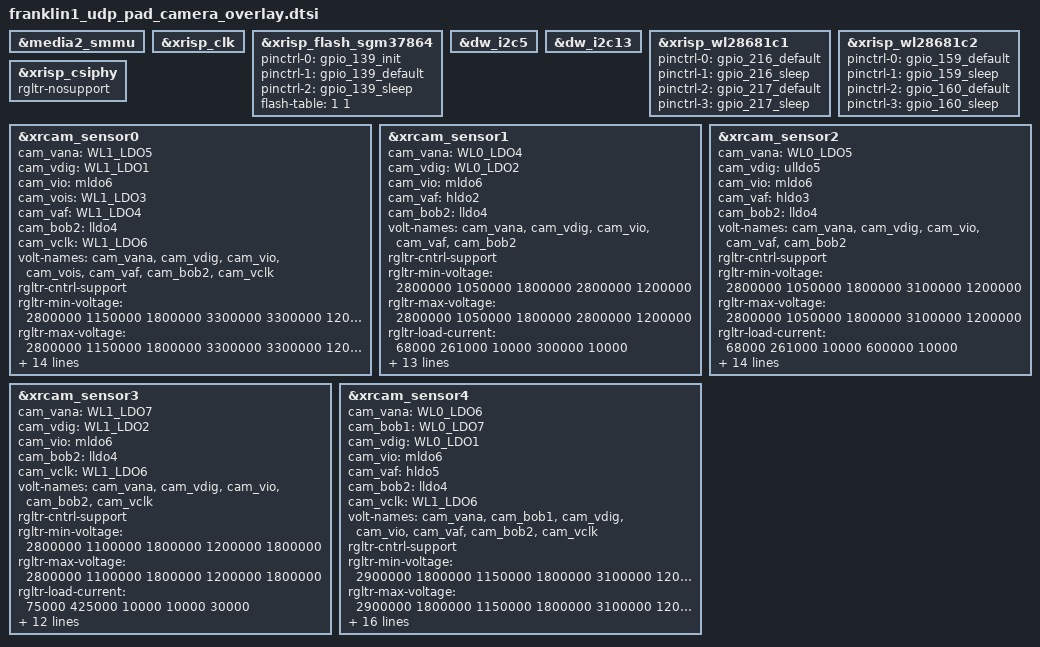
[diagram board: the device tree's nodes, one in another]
// SPDX-License-Identifier: GPL-2.0+
/*
 * vpu subsystem overlay dts for X-Ring Franklin
 *
 * (C) Copyright 2023 - 2023, X-Ring, Inc.
 */

#include <dt-bindings/xring/xr-o1-clock.h>

&media2_smmu {
	status = "okay";
};

&xrisp_clk {
	status = "okay";
};

&xrisp_flash_sgm37864 {
	status = "okay";
	pinctrl-names = "init", "default", "sleep";
	pinctrl-0 = <&gpio_139_init>;
	pinctrl-1 = <&gpio_139_default>;
	pinctrl-2 = <&gpio_139_sleep>;
	flash-table = <1 1>;
};

&dw_i2c5 {
	status = "okay";
};

&dw_i2c13 {
	status = "okay";
};

&xrisp_wl28681c1 {
	status = "okay";
	pinctrl-names ="gpio_216_default","gpio_216_sleep",
			"gpio_217_default","gpio_217_sleep";
	pinctrl-0 = <&gpio_216_default>;
	pinctrl-1 = <&gpio_216_sleep>;
	pinctrl-2 = <&gpio_217_default>;
	pinctrl-3 = <&gpio_217_sleep>;
};

&xrisp_wl28681c2 {
	status = "okay";
	pinctrl-names ="gpio_159_default","gpio_159_sleep",
			"gpio_160_default","gpio_160_sleep";
	pinctrl-0 = <&gpio_159_default>;
	pinctrl-1 = <&gpio_159_sleep>;
	pinctrl-2 = <&gpio_160_default>;
	pinctrl-3 = <&gpio_160_sleep>;
};

&xrisp_csiphy {
	status = "okay";
	rgltr-nosupport;
};

&xrcam_sensor0 {
	status = "okay";
	cam_vana  = "WL1_LDO5";
	cam_vdig  = "WL1_LDO1";
	cam_vio   = "mldo6";
	cam_vois  = "WL1_LDO3";
	cam_vaf   = "WL1_LDO4";
	cam_bob2  = "lldo4";
	cam_vclk  = "WL1_LDO6";
	volt-names = "cam_vana", "cam_vdig", "cam_vio",
		"cam_vois", "cam_vaf", "cam_bob2", "cam_vclk";
	rgltr-cntrl-support;
	rgltr-min-voltage = <2800000 1150000 1800000 3300000 3300000 1200000 1800000>;
	rgltr-max-voltage = <2800000 1150000 1800000 3300000 3300000 1200000 1800000>;
	rgltr-load-current = <195000 990000 10000 300000 3000000 10000 30000>;
	pinctrl-names = "cam_active", "cam_sleep", "cci_active", "cci_sleep";
	pinctrl-0 =
		<&gpio_151_default
		 &gpio_218_default>;
	pinctrl-1 =
		<&gpio_151_sleep
		 &gpio_218_sleep>;
	pinctrl-2 =
		<&i3c7_scl_default
		 &i3c7_sda_default>;
	pinctrl-3 =
		<&i3c7_scl_sleep
		 &i3c7_sda_sleep>;
	gpios =
		<&dw_gpio5 6  0>,   // wide sensor gpio151, oscillator
		<&dw_gpio7 3  0>,   // wide sensor gpio218
		<&dw_gpio3 14 0>;   // wl2848D33 en_gpio95
	gpio-mclk  = <0>;
	gpio-rst   = <1>;
	gpio-apert = <2>;
	gpio-req-tab-idx = <0 1 2>;
	gpio-req-tab-flags = <0 0 0>;
	gpio-req-tab-label = "gpio_mclk", "gpio_rst", "gpio_apert";
};

&xrcam_sensor1 {
	status = "okay";
	cam_vana  = "WL0_LDO4";
	cam_vdig  = "WL0_LDO2";
	cam_vio   = "mldo6";
	cam_vaf   = "hldo2";
	cam_bob2  = "lldo4";
	volt-names = "cam_vana", "cam_vdig", "cam_vio", "cam_vaf",
		"cam_bob2";
	rgltr-cntrl-support;
	rgltr-min-voltage  = <2800000 1050000 1800000 2800000 1200000>;
	rgltr-max-voltage  = <2800000 1050000 1800000 2800000 1200000>;
	rgltr-load-current = <68000 261000 10000 300000 10000>;
	pinctrl-names = "cam_active", "cam_sleep", "cci_active", "cci_sleep";
	pinctrl-0 =
		<&camf_clk_default
		 &gpio_213_default>;
	pinctrl-1 =
		<&camf_clk_sleep
		 &gpio_213_sleep>;
	pinctrl-2 =
		<&i2c22_scl_default
		 &i2c22_sda_default>;
	pinctrl-3 =
		<&i2c22_scl_sleep
		 &i2c22_sda_sleep>;
	gpios =
		<&dw_gpio7 11  0>,  // uwide sensor gpio226, mclk
		<&dw_gpio6 30 0>;   // uwide sensor gpio213
	gpio-rst   = <1>;
	gpio-req-tab-idx = <1>;
	gpio-req-tab-flags = <0>;
	gpio-req-tab-label = "gpio_rst";
	clocks = <&xr_clk XR_CLK_CAM0>;
	clock-names = "cam_mclk";
	clock-cntl-level = "normal";
	clock-rates = <19200000>;
};

&xrcam_sensor2 {
	status = "okay";
	cam_vana = "WL0_LDO5";
	cam_vdig  = "ulldo5";
	cam_vio  = "mldo6";
	cam_vaf  = "hldo3";
	cam_bob2 = "lldo4";
	volt-names = "cam_vana", "cam_vdig", "cam_vio", "cam_vaf", "cam_bob2";
	rgltr-cntrl-support;
	rgltr-min-voltage  = <2800000 1050000 1800000 3100000 1200000>;
	rgltr-max-voltage  = <2800000 1050000 1800000 3100000 1200000>;
	rgltr-load-current = <68000 261000 10000 600000 10000>;
	pinctrl-names = "cam_active", "cam_sleep", "cci_active", "cci_sleep";
	pinctrl-0 =
		<&camt_clk_default
		 &gpio_192_default
		 &gpio_096_default>;
	pinctrl-1 =
		<&camt_clk_sleep
		 &gpio_192_sleep
		 &gpio_096_sleep>;
	pinctrl-2 =
		<&i3c5_scl_default
		 &i3c5_sda_default>;
	pinctrl-3 =
		<&i3c5_scl_sleep
		 &i3c5_sda_sleep>;
	gpios =
		<&dw_gpio7 9 0>,    // tele sensor gpio224, mclk
		<&dw_gpio6 9 0>;    // tele sensor gpio192
	gpio-rst   = <1>;
	gpio-req-tab-idx = <1>;
	gpio-req-tab-flags = <0>;
	gpio-req-tab-label = "gpio_rst";
	clocks = <&xr_clk XR_CLK_CAM2>;
	clock-names = "cam_mclk";
	clock-cntl-level = "normal";
	clock-rates = <19200000>;
};

&xrcam_sensor3 {
	status = "okay";
	cam_vana  = "WL1_LDO7";
	cam_vdig  = "WL1_LDO2";
	cam_vio   = "mldo6";
	cam_bob2  = "lldo4";
	cam_vclk  = "WL1_LDO6";
	volt-names = "cam_vana","cam_vdig","cam_vio","cam_bob2", "cam_vclk";
	rgltr-cntrl-support;
	rgltr-min-voltage  = <2800000 1100000 1800000 1200000 1800000>;
	rgltr-max-voltage  = <2800000 1100000 1800000 1200000 1800000>;
	rgltr-load-current = <75000 425000 10000 10000 30000>;
	pinctrl-names = "cam_active", "cam_sleep", "cci_active", "cci_sleep";
	pinctrl-0 =
		<&gpio_088_default
		 &gpio_195_default>;
	pinctrl-1 =
		<&gpio_088_sleep
		 &gpio_195_sleep>;
	pinctrl-2 =
		<&i3c4_scl_default
		 &i3c4_sda_default>;
	pinctrl-3 =
		<&i3c4_scl_sleep
		 &i3c4_sda_sleep>;
	gpios =
		<&dw_gpio3 7 0>,  // front sensor gpio88, oscillator
		<&dw_gpio6 12 0>; // front sensor gpio195
	gpio-mclk  = <0>;
	gpio-rst   = <1>;
	gpio-req-tab-idx = <0 1>;
	gpio-req-tab-flags = <0 0>;
	gpio-req-tab-label = "gpio_mclk", "gpio_rst";
	interrupt-parent = <&gic>;
	interrupts = <GIC_SPI 40 IRQ_TYPE_LEVEL_HIGH>;
};

&xrcam_sensor4 {
	status = "okay";
	cam_vana = "WL0_LDO6";
	cam_bob1 = "WL0_LDO7";
	cam_vdig  = "WL0_LDO1";
	cam_vio   = "mldo6";
	cam_vaf   = "hldo5";
	cam_bob2  = "lldo4";
	cam_vclk  = "WL1_LDO6";
	volt-names = "cam_vana", "cam_bob1", "cam_vdig","cam_vio",
		"cam_vaf", "cam_bob2", "cam_vclk";
	rgltr-cntrl-support;
	rgltr-min-voltage = <2900000 1800000 1150000 1800000 3100000 1200000 1800000>;
	rgltr-max-voltage = <2900000 1800000 1150000 1800000 3100000 1200000 1800000>;
	rgltr-load-current = <220000 150000 975000 10000 300000 10000 30000>;
	pinctrl-names = "cam_active", "cam_sleep", "cci_active", "cci_sleep";
	pinctrl-0 =
		<&gpio_087_default
		 &gpio_207_default
		 &gpio_132_default>;
	pinctrl-1 =
		<&gpio_087_sleep
		 &gpio_207_sleep
		 &gpio_132_sleep>;
	pinctrl-2 =
		<&i3c6_scl_default
		 &i3c6_sda_default>;
	pinctrl-3 =
		<&i3c6_scl_sleep
		 &i3c6_sda_sleep>;
	gpios =
		<&dw_gpio3 6 0>,   // wide sensor gpio087, oscillator
		<&dw_gpio6 24 0>,  // wide sensor gpio207
		<&dw_gpio4 19 0>;  // wide sensor ois_vdd gpio132
	gpio-mclk  = <0>;
	gpio-rst   = <1>;
	gpio-vois  = <2>;
	gpio-req-tab-idx = <0 1 2>;
	gpio-req-tab-flags = <0 0 0>;
	gpio-req-tab-label = "gpio_mclk", "gpio_rst", "gpio_vois";
};
